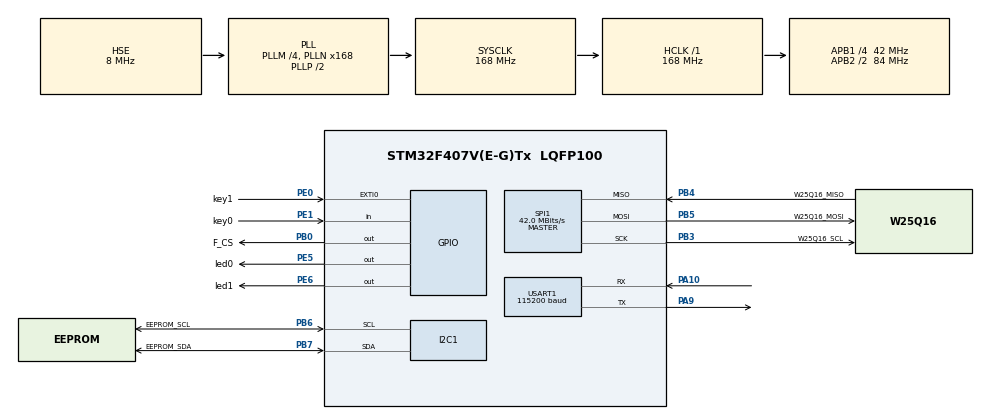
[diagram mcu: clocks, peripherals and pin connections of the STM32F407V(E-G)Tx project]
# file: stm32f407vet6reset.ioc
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Dma.Request0=USART1_RX
Dma.USART1_RX.0.Direction=DMA_PERIPH_TO_MEMORY
Dma.USART1_RX.0.FIFOMode=DMA_FIFOMODE_DISABLE
Dma.USART1_RX.0.Instance=DMA2_Stream2
Dma.USART1_RX.0.MemDataAlignment=DMA_MDATAALIGN_BYTE
Dma.USART1_RX.0.MemInc=DMA_MINC_ENABLE
Dma.USART1_RX.0.Mode=DMA_CIRCULAR
Dma.USART1_RX.0.PeriphDataAlignment=DMA_PDATAALIGN_BYTE
Dma.USART1_RX.0.PeriphInc=DMA_PINC_DISABLE
Dma.USART1_RX.0.Priority=DMA_PRIORITY_LOW
I2C1.I2C_Mode=I2C_Fast
Mcu.Family=STM32F4
Mcu.Name=STM32F407V(E-G)Tx
Mcu.Package=LQFP100
NVIC.DMA2_Stream2_IRQn=true\:0\:0\:false\:false\:true\:false\:true\:true
NVIC.EXTI0_IRQn=true\:4\:0\:true\:false\:true\:true\:true\:true
NVIC.PriorityGroup=NVIC_PRIORITYGROUP_4
NVIC.USART1_IRQn=true\:5\:0\:true\:false\:true\:true\:true\:true
PA10.Mode=Asynchronous
PA10.Signal=USART1_RX
PA13.Mode=Serial_Wire
PA13.Signal=SYS_JTMS-SWDIO
PA14.Mode=Serial_Wire
PA14.Signal=SYS_JTCK-SWCLK
PA9.Mode=Asynchronous
PA9.Signal=USART1_TX
PB0.GPIO_Label=F_CS
PB0.PinState=GPIO_PIN_SET
PB0.Signal=GPIO_Output
PB3.GPIO_Label=W25Q16_SCL
PB3.Mode=Full_Duplex_Master
PB3.Signal=SPI1_SCK
PB4.GPIO_Label=W25Q16_MISO
PB4.Mode=Full_Duplex_Master
PB4.Signal=SPI1_MISO
PB5.GPIO_Label=W25Q16_MOSI
PB5.Mode=Full_Duplex_Master
PB5.Signal=SPI1_MOSI
PB6.GPIO_Label=EEPROM_SCL
PB6.Mode=I2C
PB6.Signal=I2C1_SCL
PB7.GPIO_Label=EEPROM_SDA
PB7.Mode=I2C
PB7.Signal=I2C1_SDA
PC14-OSC32_IN.Mode=LSE-External-Oscillator
PC14-OSC32_IN.Signal=RCC_OSC32_IN
PC15-OSC32_OUT.Mode=LSE-External-Oscillator
PC15-OSC32_OUT.Signal=RCC_OSC32_OUT
PE0.GPIO_Label=key1
PE0.GPIO_ModeDefaultEXTI=GPIO_MODE_IT_FALLING
PE0.GPIO_PuPd=GPIO_PULLUP
PE0.Signal=GPXTI0
PE1.GPIO_Label=key0
PE1.GPIO_PuPd=GPIO_PULLUP
PE1.Signal=GPIO_Input
PE5.GPIO_Label=led0
PE5.GPIO_PuPd=GPIO_PULLUP
PE5.PinState=GPIO_PIN_SET
PE5.Signal=GPIO_Output
PE6.GPIO_Label=led1
PE6.GPIO_PuPd=GPIO_PULLUP
PE6.PinState=GPIO_PIN_SET
PE6.Signal=GPIO_Output
PH0-OSC_IN.Mode=HSE-External-Oscillator
PH0-OSC_IN.Signal=RCC_OSC_IN
PH1-OSC_OUT.Mode=HSE-External-Oscillator
PH1-OSC_OUT.Signal=RCC_OSC_OUT
ProjectManager.HeapSize=0x200
ProjectManager.StackSize=0x400
ProjectManager.TargetToolchain=MDK-ARM V5.32
RCC.48MHZClocksFreq_Value=84000000
RCC.AHBFreq_Value=168000000
RCC.APB1CLKDivider=RCC_HCLK_DIV4
RCC.APB1Freq_Value=42000000
RCC.APB1TimFreq_Value=84000000
RCC.APB2CLKDivider=RCC_HCLK_DIV2
RCC.APB2Freq_Value=84000000
RCC.APB2TimFreq_Value=168000000
RCC.CortexFreq_Value=168000000
RCC.HCLKFreq_Value=168000000
RCC.HSE_VALUE=8000000
RCC.HSI_VALUE=16000000
RCC.PLLM=4
RCC.PLLN=168
RCC.PLLSource=RCC_PLLSOURCE_HSE
RCC.SYSCLKFreq_VALUE=168000000
RCC.SYSCLKSource=RCC_SYSCLKSOURCE_PLLCLK
RCC.VCOOutputFreq_Value=336000000
SPI1.CalculateBaudRate=42.0 MBits/s
SPI1.Direction=SPI_DIRECTION_2LINES
SPI1.Mode=SPI_MODE_MASTER
SPI1.VirtualType=VM_MASTER
USART1.BaudRate=115200
USART1.VirtualMode=VM_ASYNC
board=custom

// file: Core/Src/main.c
/* USER CODE BEGIN Header */
/**
 ******************************************************************************
 * @file           : main.c
 * @brief          : Main program body
 ******************************************************************************
 * @attention
 *
 * Copyright (c) 2026 STMicroelectronics.
 * All rights reserved.
 *
 * This software is licensed under terms that can be found in the LICENSE file
 * in the root directory of this software component.
 * If no LICENSE file comes with this software, it is provided AS-IS.
 *
 ******************************************************************************
 */
/* USER CODE END Header */
#include "main.h"
#include "dma.h"
#include "i2c.h"
#include "spi.h"
#include "usart.h"
#include "gpio.h"

/* USER CODE BEGIN Includes */
#include <stdio.h> // printf 声明; 缺它会触发隐式声明告警(#223-D), 重定向在 usart.c 的 fputc
#include "app_reset.h"
/* USER CODE END Includes */

/* USER CODE BEGIN PD */
#define LED_BLINK_INTERVAL_MS 500
/* USER CODE END PD */

/* USER CODE BEGIN PV */
//uint8_t read_byte;

/* USER CODE END PV */

void SystemClock_Config(void);

/* USER CODE BEGIN 0 */
#define RESET_ADDR 0x4000
/* USER CODE END 0 */

int main(void)
{

  /* USER CODE BEGIN 1 */

    /* 前级程序跳入恢复区时可能关闭中断，向量表已由 SystemInit 定位到 0x08004000。 */

  /* uint8_t manufacturer_id = 0;
  uint16_t device_id = 0; */
  // uint32_t last_print_tick;
    SCB->VTOR = FLASH_BASE | RESET_ADDR;

  __enable_irq();
  /* USER CODE END 1 */

  /* MCU Configuration--------------------------------------------------------*/

  /* Reset of all peripherals, Initializes the Flash interface and the Systick. */
  HAL_Init();

  /* Configure the system clock */
  SystemClock_Config();

  /* Initialize all configured peripherals */
  MX_GPIO_Init();
  MX_DMA_Init();
  MX_USART1_UART_Init();
  MX_I2C1_Init();
  MX_SPI1_Init();
  /* USER CODE BEGIN 2 */
  /* 上电读取一次 W25Q16 的品牌 ID 和 16 位设备 ID，通过 USART1 打印。 */
  /* int_w25q16_read_id(&manufacturer_id, &device_id);
  printf("W25Q16 Manufacturer ID:0x%d Device ID:0x%d\r\n", (unsigned int)manufacturer_id, (unsigned int)device_id);
  int_w25q16_erase_sector(0, 0);

  int_w25q16_write(0, 0, 0, 0x08, "12345678", 8);
  uint8_t data[8]={0};
  int_w25q16_read(0,0,0,0x08,data,8);
  printf("data:");
    for (uint8_t i = 0; i < 8; i++)
    {
        printf("%c", data[i]);
    } */
  /*  int_eeprom_write_byte(0x00, 'b');
   HAL_Delay(5);
   read_byte = int_eeprom_read_byte(0x00);
  printf("eeprom:%c\n",read_byte); */
  /* int_eeprom_write(0x00,"123123789723872398472",22);
  HAL_Delay(5);
  uint8_t read_buff[23]={0};
  int_eeprom_read(0x00,read_buff,22);
  printf("read_buff:%s",read_buff); */

    /* 等待串口升级命令，接收空闲确认 2 秒后校验并跳转到 APP。 */
    App_bootloader_Init();

    /*，LED0（PE5）亮 */
    HAL_GPIO_WritePin(led1_GPIO_Port, led1_Pin, GPIO_PIN_RESET);

  /* USER CODE END 2 */

  /* Infinite loop */
  while (1)
  {

    /* USER CODE BEGIN 3 */
        App_bootloader_work();

  }
  /* USER CODE END 3 */
}

void SystemClock_Config(void)
{
  RCC_OscInitTypeDef RCC_OscInitStruct = {0};
  RCC_ClkInitTypeDef RCC_ClkInitStruct = {0};

  /** Configure the main internal regulator output voltage
   */
  __HAL_RCC_PWR_CLK_ENABLE();
  __HAL_PWR_VOLTAGESCALING_CONFIG(PWR_REGULATOR_VOLTAGE_SCALE1);

  /** Initializes the RCC Oscillators according to the specified parameters
   * in the RCC_OscInitTypeDef structure.
   */
  /* 板上 Y3 为 8 MHz 无源晶振；PLL 输入保持 2 MHz，系统时钟保持 168 MHz。 */
  RCC_OscInitStruct.OscillatorType = RCC_OSCILLATORTYPE_HSE;
  RCC_OscInitStruct.HSEState = RCC_HSE_ON;
  RCC_OscInitStruct.PLL.PLLState = RCC_PLL_ON;
  RCC_OscInitStruct.PLL.PLLSource = RCC_PLLSOURCE_HSE;
  RCC_OscInitStruct.PLL.PLLM = 4;
  RCC_OscInitStruct.PLL.PLLN = 168;
  RCC_OscInitStruct.PLL.PLLP = RCC_PLLP_DIV2;
  RCC_OscInitStruct.PLL.PLLQ = 4;
  if (HAL_RCC_OscConfig(&RCC_OscInitStruct) != HAL_OK)
  {
    Error_Handler();
  }

  /** Initializes the CPU, AHB and APB buses clocks
   */
  RCC_ClkInitStruct.ClockType = RCC_CLOCKTYPE_HCLK | RCC_CLOCKTYPE_SYSCLK | RCC_CLOCKTYPE_PCLK1 | RCC_CLOCKTYPE_PCLK2;
  RCC_ClkInitStruct.SYSCLKSource = RCC_SYSCLKSOURCE_PLLCLK;
  RCC_ClkInitStruct.AHBCLKDivider = RCC_SYSCLK_DIV1;
  RCC_ClkInitStruct.APB1CLKDivider = RCC_HCLK_DIV4;
  RCC_ClkInitStruct.APB2CLKDivider = RCC_HCLK_DIV2;

  if (HAL_RCC_ClockConfig(&RCC_ClkInitStruct, FLASH_LATENCY_5) != HAL_OK)
  {
    Error_Handler();
  }
}

void Error_Handler(void)
{
  __disable_irq();
  while (1)
  {
  }
}
